AUTOSAR XML (schema 00044)
package /E40_Platform_System_SystemPackage/Components
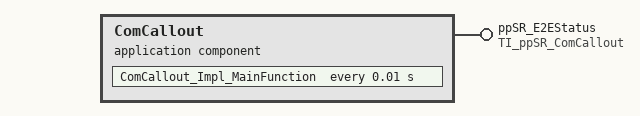
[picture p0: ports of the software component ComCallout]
  application sw component type ComCallout
    provide port ppSR_E2EStatus: nonqueued-sender-com-spec{data-element=ABS0x102_Status, init-value=constant-reference=ComCalloutABS0x102_StatusValue0}, provided-interface=TI_ppSR_ComCallout
    behavior IB_ComCallout: port-api-option{enable-take-address=false, indirect-api=false, port=ppSR_E2EStatus}
      timing event TEComCallout_Impl_MainFunction: start-on-event=ComCallout_Impl_MainFunction, period=0.01
      runnable ComCallout_Impl_MainFunction: can-be-invoked-concurrently=true
        data-send-points:
          access DWA_ppSR_E2EStatus_ABS0x102_Status: accessed-variable=ppSR_E2EStatus.ABS0x102_Status
  swc implementation IMPL_ComCallout: behavior=IB_ComCallout
